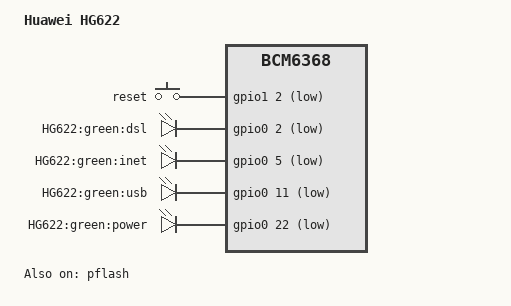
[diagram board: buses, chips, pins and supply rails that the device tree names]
/dts-v1/;

#include "bcm6368.dtsi"

#include <dt-bindings/input/input.h>

/ {
	model = "Huawei HG622";
	compatible = "huawei,hg622", "brcm,bcm6368";

	chosen {
		bootargs = "root=/dev/mtdblock2 rootfstype=squashfs,jffs2 noinitrd console=ttyS0,115200";
	};


	gpio-keys-polled {
		compatible = "gpio-keys-polled";
		#address-cells = <1>;
		#size-cells = <0>;
		poll-interval = <20>;
		debounce-interval = <60>;

		reset {
			label = "reset";
			gpios = <&gpio1 2 1>;
			linux,code = <KEY_RESTART>;
		};
	};

	gpio-leds {
		compatible = "gpio-leds";

		dsl_green {
			label = "HG622:green:dsl";
			gpios = <&gpio0 2 1>;
		};
		inet_green {
			label = "HG622:green:inet";
			gpios = <&gpio0 5 1>;
		};
		usb_green {
			label = "HG622:green:usb";
			gpios = <&gpio0 11 1>;
		};
		power_green {
			label = "HG622:green:power";
			gpios = <&gpio0 22 1>;
			default-state = "on";
		};
	};
};

&pflash {
	status = "ok";

	linux,part-probe = "bcm63xxpart";

	cfe@0 {
		label = "CFE";
		reg = <0x000000 0x020000>;
		read-only;
	};

	linux@20000 {
		label = "linux";
		reg = <0x020000 0xf80000>;
	};

	cal_data@fa0000 {
		label = "cal_data";
		reg = <0xfa0000 0x020000>;
		read-only;
	};

	nvram@fe0000 {
		label = "nvram";
		reg = <0xfe0000 0x020000>;
	};
};
